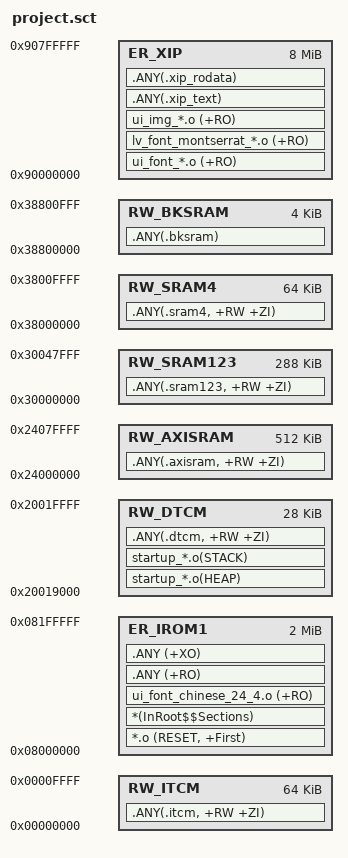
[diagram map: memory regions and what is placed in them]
; *************************************************************
; *** Scatter-Loading Description File generated by uVision ***
; *************************************************************

LR_IROM1 0x08000000 0x00200000  {    ; 2MB load region size_region
  ER_IROM1 0x08000000 0x00200000  {  ; 2MB load address = execution address
   *.o (RESET, +First)
   *(InRoot$$Sections)
   ; 主界面和多数App高频使用的24px字体保留在内部Flash，避免QSPI随机读取带来的延迟。
   ui_font_chinese_24_4.o (+RO)
   .ANY (+RO)
   .ANY (+XO)
  }
  
  RW_ITCM 0x00000000 0x00010000  {    ; 64KB ITCM
	.ANY(.itcm, +RW +ZI) 
  }
  
  ;RW_DTCM 0x20000000 0x00020000  {   ; 128KB DTCM
  RW_DTCM 0x20019000 0x00007000  {    ; 28KB DTCM，前100KB分配给LVGL内存池
	startup_*.o(HEAP)
	startup_*.o(STACK)
	.ANY(.dtcm, +RW +ZI)
  }
  
  RW_AXISRAM 0x24000000 0x00080000  {  ; RW data : 512KB AXI SRAM
	.ANY(.axisram, +RW +ZI) 
  }

  RW_SRAM123 0x30000000 0x00048000  {  ; RW data : 128KB SRAM1(0x30000000) + 128KB SRAM2(0x3002 0000) + 32KB SRAM3(0x30040000) = 288KB
    .ANY(.sram123, +RW +ZI)
  }

  RW_SRAM4 0x38000000 0x00010000  {  ; RW data : 64KB SRAM4(0x38000000)
    .ANY(.sram4, +RW +ZI)
  }
  
  RW_BKSRAM 0x38800000 0x00001000  {  ; RW data : 4KB BKSRAM
    .ANY(.bksram)
  }
}

; 外部W25Q64独立加载区：由FK743M5_XIH6_V0.FLM写入，运行时从0x90000000直接取指。
LR_XIP 0x90000000 0x00800000  {
  ER_XIP 0x90000000 0x00800000  {
    ; 除24px主字体外，仅迁移资源对象的RO段；字体glyph cache等RW/ZI数据仍由内部RAM区域接收。
    ui_font_*.o (+RO)
    lv_font_montserrat_*.o (+RO)
    ui_img_*.o (+RO)
    .ANY(.xip_text)
    .ANY(.xip_rodata)
  }
}

